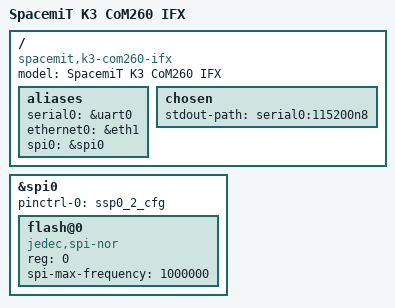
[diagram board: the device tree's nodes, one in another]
// SPDX-License-Identifier: (GPL-2.0 OR MIT)
/*
 * Copyright (c) 2026 SpacemiT (Hangzhou) Technology Co. Ltd
 * Copyright (c) 2026 Yixun Lan <dlan@kernel.org>
 */

#include "k3-com260.dtsi"

/ {
	model = "SpacemiT K3 CoM260 IFX";
	compatible = "spacemit,k3-com260-ifx", "spacemit,k3-com260", "spacemit,k3";

	aliases {
		serial0 = &uart0;
		ethernet0 = &eth1;
		spi0 = &spi0;
	};

	chosen {
		stdout-path = "serial0:115200n8";
	};
};

&spi0 {
	pinctrl-names = "default";
	pinctrl-0 = <&ssp0_2_cfg>;
	status = "okay";

	flash@0 {
		compatible = "jedec,spi-nor";
		reg = <0>;
		spi-max-frequency = <1000000>;
	};
};
